# IMM100A register map
Vendor: Infineon; File version: 0.8.0 (Reference Manual v0.8.0)
CPU: CM0 r0p0, little endian, no MPU, no FPU, 2 interrupt priority bits
Registers are 32-bit, read-write, reset 0x0 unless marked. A register's access mark holds for its fields unless they carry their own. Offsets are from the block's base; [hi:lo] are bit positions; {n}, {i} and the like mark numbered series; 'fields as' and 'values as' point back to an identical list.

## SHS0 — Sample and Hold ADC Sequencer
Base 0x48034000
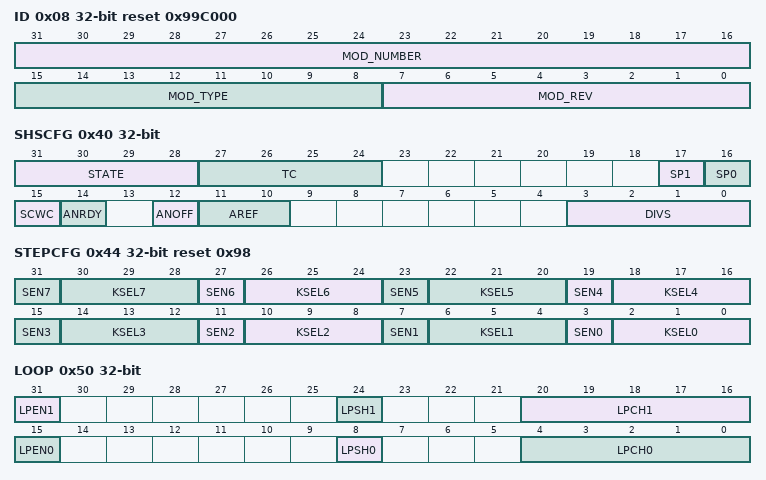
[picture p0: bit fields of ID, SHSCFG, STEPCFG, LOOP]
0x08 ID ro reset 0x99C000 (reset mask 0xFFFFFF00) — Module Identification Register
  [31:16] MOD_NUMBER — Module Number
  [15:8] MOD_TYPE — Module Type
  [7:0] MOD_REV — Module Revision
0x40 SHSCFG access per field — SHS Configuration Register
  [31:28] STATE ro — Current State of Sequencer
    0=Idle; 1=Offset calibration active; 2=Gain calibration active; 3=Startup calibration active; 8=Stepper process active for S&H unit 0; 9=Stepper process active for S&H unit 1
  [27:24] TC rw — Test Control
    11=Internal test functions enabled
  [17] SP1 ro — Sample Pending on S&H Unit x
    0=No sample pending; 1=S&H unit x has finished the sample phase
  [16] SP0 ro — Sample Pending on S&H Unit x
    values as SP1
  [15] SCWC wo — Write Control for SHS Configuration
    0=No write access to SHS configuration; 1=Bitfields ANOFF, AREF, DIVS can be written
  [14] ANRDY ro — Analog Converter Ready
    0=Converter is in power-down mode; 1=Converter is operable
  [12] ANOFF rw — Analog Converter Power Down Force
    0=Converter controlled by bitfields ANONS (digital control block); 1=Converter is permanently off
  [11:10] AREF rw — Analog Calbration Reference Voltage Selection
    0=External reference, upper supply range; 2=Internal reference, upper supply range; 3=Internal reference, lower supply range
  [3:0] DIVS rw — Divider Factor for the SHS Clock
    0=fSH = fCONV / 1; 1=fSH = fCONV / 2; 7=fSH = fCONV / 8
0x44 STEPCFG reset 0x98 — Stepper Configuration Register
  [4n+3] SEN{n} (n=0..7) — Step x Enable
    0=Off: This step is not part of the stepper sequence; 1=Active: This step is executed during the sequence
  [4n+2:4n] KSEL{n} (n=0..7) — Kernel Select
0x50 LOOP — Loop Control Register
  [31] LPEN1 — Loop y Enable
    0=Off: standard operation; 1=ON: sigma-delta-loop is active
  [24] LPSH1 — Loop y Sample&Hold Unit
  [20:16] LPCH1 — Loop y Channel
  [15] LPEN0 — Loop y Enable
    0=Off: standard operation; 1=ON: sigma-delta-loop is active
  [8] LPSH0 — Loop y Sample&Hold Unit
  [4:0] LPCH0 — Loop y Channel
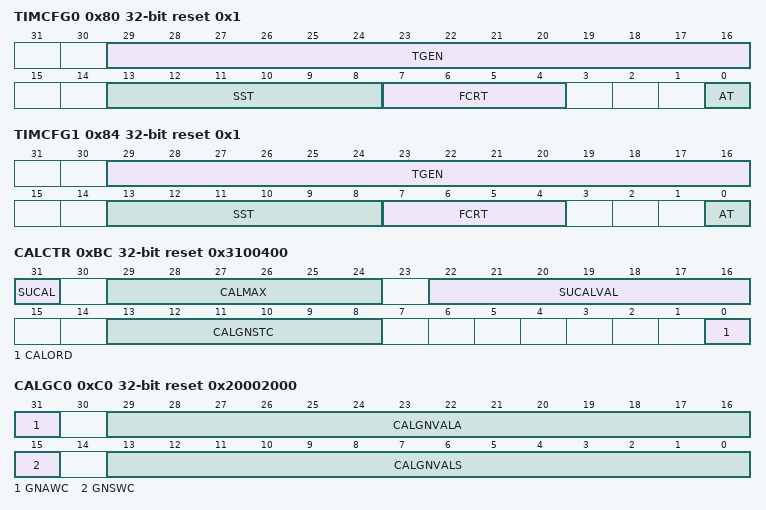
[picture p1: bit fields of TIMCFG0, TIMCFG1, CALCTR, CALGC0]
0x80 TIMCFG0 access per field reset 0x1 — Timing Configuration Register 0
  [29:16] TGEN ro — Timing Generator
  [13:8] SST rw — Short Sample Time
    0=Compatible timing: Sample time is defined by DIVA and STC; 1=Sample time is tADC x 1; 63=Sample time is tADC x 63
  [7:4] FCRT rw — Fast Compare Mode Response Time
    0=Result after tADCI x 2; 15=Result after tADCI x 32
  [0] AT rw — Accelerated Timing
    0=Compatible timing: Result available after standard conversion time; 1=Accelerated timing: Result available as soon as converted
0x84 TIMCFG1 access per field reset 0x1 — Timing Configuration Register 1
  fields as TIMCFG0
0xBC CALCTR access per field reset 0x3100400 — Calibration Control Register
  [31] SUCAL wo — Start-Up Calibration
    0=No action; 1=Initiate the start-up calibration phase (indication in bitfield SHSCFG.STATE)
  [29:24] CALMAX rw — Calibration Maximum Timing
  [22:16] SUCALVAL rw — Startup Calibration Cycles
  [13:8] CALGNSTC rw — Gain Calibration Sample Time Control
  [0] CALORD rw — Calibration Order
    0=Do conversions then calibration; 1=Do calibration then conversions
0xC0 CALGC0 access per field reset 0x20002000 — Gain Calibration Control Register 0
  [31] GNAWC wo — Gain Calibration Write Control, Alternate
    0=No write access to gain calibration parameter; 1=CALGNVALA can be written
  [29:16] CALGNVALA rw — Gain Calibration Value, Alternate Reference
  [15] GNSWC wo — Gain Calibration Write Control, Standard
    0=No write access to gain calibration parameter; 1=CALGNVALS can be written
  [13:0] CALGNVALS rw — Gain Calibration Value, Standard Reference
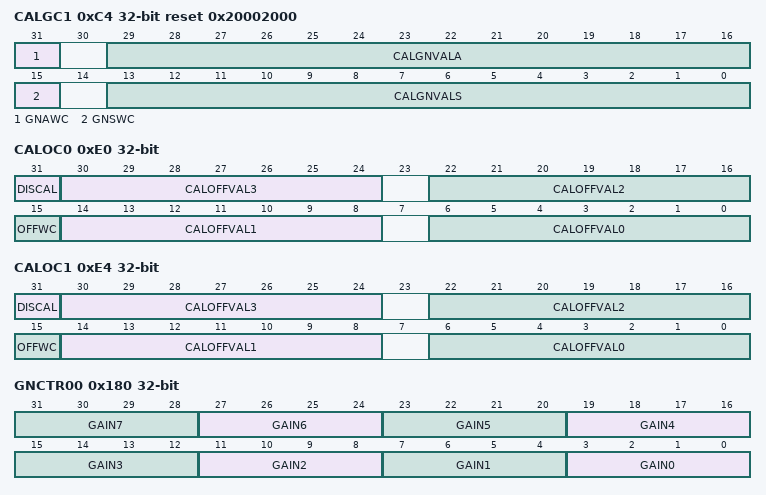
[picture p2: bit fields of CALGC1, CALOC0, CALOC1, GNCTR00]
0xC4 CALGC1 access per field reset 0x20002000 — Gain Calibration Control Register 1
  fields as CALGC0
0xE0 CALOC0 access per field — Offset Calibration Control Register 0
  [31] DISCAL rw — Disable Calibration
    0=Calibration enabled (offset and gain); 1=No calibration
  [8n+6:8n] CALOFFVAL{n} rw (n=0..3) — Offset Calibration Value for Gain Level z
  [15] OFFWC wo — Offset Calibration Write Control
    0=No write access to offset cal. parameters; 1=CALOFFVALz can be written
0xE4 CALOC1 access per field — Offset Calibration Control Register 1
  fields as CALOC0
0x180 GNCTR00 — Gain Control Register 00
  [all] fields
    0=Gain factor = 1; 1=Gain factor = 3; 2=Gain factor = 6; 3=Gain factor = 12
  [4n+3:4n] GAIN{n} (n=0..7) — Gain Control {n}
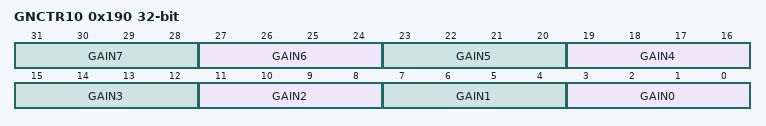
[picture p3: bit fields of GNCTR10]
0x190 GNCTR10 — Gain Control Register 10
  fields as GNCTR00
